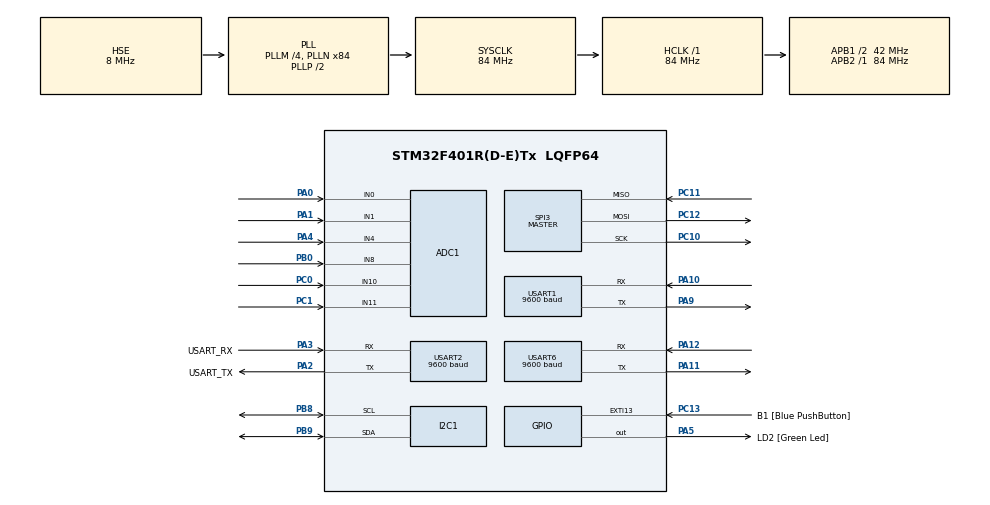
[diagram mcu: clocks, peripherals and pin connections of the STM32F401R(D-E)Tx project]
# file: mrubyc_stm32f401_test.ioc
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ADC1.Channel-0\#ChannelRegularConversion=ADC_CHANNEL_0
ADC1.NbrOfConversionFlag=1
ADC1.Rank-0\#ChannelRegularConversion=1
ADC1.SamplingTime-0\#ChannelRegularConversion=ADC_SAMPLETIME_3CYCLES
ADC1.master=1
Dma.Request0=USART1_RX
Dma.Request1=USART2_RX
Dma.Request2=USART6_RX
Dma.USART1_RX.0.Direction=DMA_PERIPH_TO_MEMORY
Dma.USART1_RX.0.FIFOMode=DMA_FIFOMODE_DISABLE
Dma.USART1_RX.0.Instance=DMA2_Stream2
Dma.USART1_RX.0.MemDataAlignment=DMA_MDATAALIGN_BYTE
Dma.USART1_RX.0.MemInc=DMA_MINC_ENABLE
Dma.USART1_RX.0.Mode=DMA_CIRCULAR
Dma.USART1_RX.0.PeriphDataAlignment=DMA_PDATAALIGN_BYTE
Dma.USART1_RX.0.PeriphInc=DMA_PINC_DISABLE
Dma.USART1_RX.0.Priority=DMA_PRIORITY_LOW
Dma.USART2_RX.1.Direction=DMA_PERIPH_TO_MEMORY
Dma.USART2_RX.1.FIFOMode=DMA_FIFOMODE_DISABLE
Dma.USART2_RX.1.Instance=DMA1_Stream5
Dma.USART2_RX.1.MemDataAlignment=DMA_MDATAALIGN_BYTE
Dma.USART2_RX.1.MemInc=DMA_MINC_ENABLE
Dma.USART2_RX.1.Mode=DMA_CIRCULAR
Dma.USART2_RX.1.PeriphDataAlignment=DMA_PDATAALIGN_BYTE
Dma.USART2_RX.1.PeriphInc=DMA_PINC_DISABLE
Dma.USART2_RX.1.Priority=DMA_PRIORITY_LOW
Dma.USART6_RX.2.Direction=DMA_PERIPH_TO_MEMORY
Dma.USART6_RX.2.FIFOMode=DMA_FIFOMODE_DISABLE
Dma.USART6_RX.2.Instance=DMA2_Stream1
Dma.USART6_RX.2.MemDataAlignment=DMA_MDATAALIGN_BYTE
Dma.USART6_RX.2.MemInc=DMA_MINC_ENABLE
Dma.USART6_RX.2.Mode=DMA_CIRCULAR
Dma.USART6_RX.2.PeriphDataAlignment=DMA_PDATAALIGN_BYTE
Dma.USART6_RX.2.PeriphInc=DMA_PINC_DISABLE
Dma.USART6_RX.2.Priority=DMA_PRIORITY_LOW
Mcu.Family=STM32F4
Mcu.Name=STM32F401R(D-E)Tx
Mcu.Package=LQFP64
NVIC.DMA1_Stream5_IRQn=true\:0\:0\:false\:false\:true\:false\:true\:true
NVIC.DMA2_Stream1_IRQn=true\:0\:0\:false\:false\:true\:false\:true\:true
NVIC.DMA2_Stream2_IRQn=true\:0\:0\:false\:false\:true\:false\:true\:true
NVIC.PriorityGroup=NVIC_PRIORITYGROUP_0
PA0-WKUP.Signal=ADCx_IN0
PA1.Signal=ADCx_IN1
PA10.Mode=Asynchronous
PA10.Signal=USART1_RX
PA11.Mode=Asynchronous
PA11.Signal=USART6_TX
PA12.Mode=Asynchronous
PA12.Signal=USART6_RX
PA13.GPIO_Label=TMS
PA13.Mode=Serial_Wire
PA13.Signal=SYS_JTMS-SWDIO
PA14.GPIO_Label=TCK
PA14.Mode=Serial_Wire
PA14.Signal=SYS_JTCK-SWCLK
PA2.GPIO_Label=USART_TX
PA2.GPIO_Mode=GPIO_MODE_AF_PP
PA2.GPIO_PuPd=GPIO_NOPULL
PA2.GPIO_Speed=GPIO_SPEED_FREQ_LOW
PA2.Mode=Asynchronous
PA2.Signal=USART2_TX
PA3.GPIO_Label=USART_RX
PA3.GPIO_Mode=GPIO_MODE_AF_PP
PA3.GPIO_PuPd=GPIO_NOPULL
PA3.GPIO_Speed=GPIO_SPEED_FREQ_LOW
PA3.Mode=Asynchronous
PA3.Signal=USART2_RX
PA4.Signal=ADCx_IN4
PA5.GPIO_Label=LD2 [Green Led]
PA5.GPIO_Mode=GPIO_MODE_OUTPUT_PP
PA5.GPIO_PuPd=GPIO_NOPULL
PA5.GPIO_Speed=GPIO_SPEED_FREQ_LOW
PA5.Signal=GPIO_Output
PA9.Mode=Asynchronous
PA9.Signal=USART1_TX
PB0.Signal=ADCx_IN8
PB3.GPIO_Label=SWO
PB3.Signal=SYS_JTDO-SWO
PB8.Mode=I2C
PB8.Signal=I2C1_SCL
PB9.Mode=I2C
PB9.Signal=I2C1_SDA
PC0.Signal=ADCx_IN10
PC1.Signal=ADCx_IN11
PC10.Mode=Full_Duplex_Master
PC10.Signal=SPI3_SCK
PC11.Mode=Full_Duplex_Master
PC11.Signal=SPI3_MISO
PC12.Mode=Full_Duplex_Master
PC12.Signal=SPI3_MOSI
PC13-ANTI_TAMP.GPIO_Label=B1 [Blue PushButton]
PC13-ANTI_TAMP.GPIO_ModeDefaultEXTI=GPIO_MODE_IT_FALLING
PC13-ANTI_TAMP.GPIO_PuPd=GPIO_NOPULL
PC13-ANTI_TAMP.Signal=GPXTI13
PC14-OSC32_IN.Mode=LSE-External-Oscillator
PC14-OSC32_IN.Signal=RCC_OSC32_IN
PC15-OSC32_OUT.Mode=LSE-External-Oscillator
PC15-OSC32_OUT.Signal=RCC_OSC32_OUT
PH0\ -\ OSC_IN.Mode=HSE-External-Clock-Source
PH0\ -\ OSC_IN.Signal=RCC_OSC_IN
PH1\ -\ OSC_OUT.Mode=HSE-External-Clock-Source
PH1\ -\ OSC_OUT.Signal=RCC_OSC_OUT
ProjectManager.HeapSize=0x200
ProjectManager.StackSize=0x400
ProjectManager.TargetToolchain=STM32CubeIDE
RCC.48MHZClocksFreq_Value=24000000
RCC.AHBFreq_Value=84000000
RCC.APB1CLKDivider=RCC_HCLK_DIV2
RCC.APB1Freq_Value=42000000
RCC.APB1TimFreq_Value=84000000
RCC.APB2Freq_Value=84000000
RCC.APB2TimFreq_Value=84000000
RCC.CortexFreq_Value=84000000
RCC.HCLKFreq_Value=84000000
RCC.HSE_VALUE=8000000
RCC.HSI_VALUE=16000000
RCC.PLLM=4
RCC.PLLN=84
RCC.PLLQ=7
RCC.PLLSourceVirtual=RCC_PLLSOURCE_HSE
RCC.SYSCLKFreq_VALUE=84000000
RCC.SYSCLKSource=RCC_SYSCLKSOURCE_PLLCLK
RCC.VCOOutputFreq_Value=168000000
SH.ADCx_IN0.0=ADC1_IN0,IN0
SH.ADCx_IN1.0=ADC1_IN1,IN1
SH.ADCx_IN10.0=ADC1_IN10,IN10
SH.ADCx_IN11.0=ADC1_IN11,IN11
SH.ADCx_IN4.0=ADC1_IN4,IN4
SH.ADCx_IN8.0=ADC1_IN8,IN8
SPI3.BaudRatePrescaler=SPI_BAUDRATEPRESCALER_64
SPI3.Direction=SPI_DIRECTION_2LINES
SPI3.Mode=SPI_MODE_MASTER
SPI3.VirtualType=VM_MASTER
TIM1.Channel-PWM\ Generation1\ No\ Output=TIM_CHANNEL_1
TIM1.Period=1
TIM2.Channel-PWM\ Generation1\ No\ Output=TIM_CHANNEL_1
TIM2.Channel-PWM\ Generation2\ No\ Output=TIM_CHANNEL_2
TIM2.Channel-PWM\ Generation3\ No\ Output=TIM_CHANNEL_3
TIM2.Period=1
TIM3.Channel-PWM\ Generation1\ No\ Output=TIM_CHANNEL_1
TIM3.Channel-PWM\ Generation2\ No\ Output=TIM_CHANNEL_2
TIM3.Channel-PWM\ Generation3\ No\ Output=TIM_CHANNEL_3
TIM3.Period=1
TIM4.Channel-PWM\ Generation2\ No\ Output=TIM_CHANNEL_2
TIM4.Period=1
USART1.BaudRate=9600
USART1.VirtualMode=VM_ASYNC
USART2.BaudRate=9600
USART2.VirtualMode=VM_ASYNC
USART6.BaudRate=9600
USART6.VirtualMode=VM_ASYNC
VP_TIM1_VS_ClockSourceINT.Mode=Internal
VP_TIM1_VS_no_output1.Mode=PWM Generation1 No Output
VP_TIM2_VS_ClockSourceINT.Mode=Internal
VP_TIM2_VS_no_output1.Mode=PWM Generation1 No Output
VP_TIM2_VS_no_output2.Mode=PWM Generation2 No Output
VP_TIM2_VS_no_output3.Mode=PWM Generation3 No Output
VP_TIM3_VS_ClockSourceINT.Mode=Internal
VP_TIM3_VS_no_output1.Mode=PWM Generation1 No Output
VP_TIM3_VS_no_output2.Mode=PWM Generation2 No Output
VP_TIM3_VS_no_output3.Mode=PWM Generation3 No Output
VP_TIM4_VS_ClockSourceINT.Mode=Internal
VP_TIM4_VS_no_output2.Mode=PWM Generation2 No Output
board=NUCLEO-F401RE

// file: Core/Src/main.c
/* USER CODE BEGIN Header */
/**
  ******************************************************************************
  * @file           : main.c
  * @brief          : Main program body
  ******************************************************************************
  * @attention
  *
  * Copyright (c) 2024 STMicroelectronics.
  * All rights reserved.
  *
  * This software is licensed under terms that can be found in the LICENSE file
  * in the root directory of this software component.
  * If no LICENSE file comes with this software, it is provided AS-IS.
  *
  ******************************************************************************
  */
/* USER CODE END Header */
#include "main.h"

/* USER CODE BEGIN Includes */
#include <stdio.h>

/* USER CODE END Includes */

ADC_HandleTypeDef hadc1;

I2C_HandleTypeDef hi2c1;

SPI_HandleTypeDef hspi3;

TIM_HandleTypeDef htim1;
TIM_HandleTypeDef htim2;
TIM_HandleTypeDef htim3;
TIM_HandleTypeDef htim4;

UART_HandleTypeDef huart1;
UART_HandleTypeDef huart2;
UART_HandleTypeDef huart6;
DMA_HandleTypeDef hdma_usart1_rx;
DMA_HandleTypeDef hdma_usart2_rx;
DMA_HandleTypeDef hdma_usart6_rx;

void SystemClock_Config(void);
static void MX_GPIO_Init(void);
static void MX_DMA_Init(void);
static void MX_USART2_UART_Init(void);
static void MX_ADC1_Init(void);
static void MX_I2C1_Init(void);
static void MX_SPI3_Init(void);
static void MX_USART1_UART_Init(void);
static void MX_USART6_UART_Init(void);
static void MX_TIM1_Init(void);
static void MX_TIM2_Init(void);
static void MX_TIM3_Init(void);
static void MX_TIM4_Init(void);

int main(void)
{

  /* MCU Configuration--------------------------------------------------------*/

  /* Reset of all peripherals, Initializes the Flash interface and the Systick. */
  HAL_Init();

  /* Configure the system clock */
  SystemClock_Config();

  /* Initialize all configured peripherals */
  MX_GPIO_Init();
  MX_DMA_Init();
  MX_USART2_UART_Init();
  MX_ADC1_Init();
  MX_I2C1_Init();
  MX_SPI3_Init();
  MX_USART1_UART_Init();
  MX_USART6_UART_Init();
  MX_TIM1_Init();
  MX_TIM2_Init();
  MX_TIM3_Init();
  MX_TIM4_Init();
  /* USER CODE BEGIN 2 */
  void start_mrubyc(void);
  start_mrubyc();
  /* USER CODE END 2 */

  /* Infinite loop */
  while (1)
  {

  }
}

void SystemClock_Config(void)
{
  RCC_OscInitTypeDef RCC_OscInitStruct = {0};
  RCC_ClkInitTypeDef RCC_ClkInitStruct = {0};

  /** Configure the main internal regulator output voltage
  */
  __HAL_RCC_PWR_CLK_ENABLE();
  __HAL_PWR_VOLTAGESCALING_CONFIG(PWR_REGULATOR_VOLTAGE_SCALE2);

  /** Initializes the RCC Oscillators according to the specified parameters
  * in the RCC_OscInitTypeDef structure.
  */
  RCC_OscInitStruct.OscillatorType = RCC_OSCILLATORTYPE_HSE;
  RCC_OscInitStruct.HSEState = RCC_HSE_BYPASS;
  RCC_OscInitStruct.PLL.PLLState = RCC_PLL_ON;
  RCC_OscInitStruct.PLL.PLLSource = RCC_PLLSOURCE_HSE;
  RCC_OscInitStruct.PLL.PLLM = 4;
  RCC_OscInitStruct.PLL.PLLN = 84;
  RCC_OscInitStruct.PLL.PLLP = RCC_PLLP_DIV2;
  RCC_OscInitStruct.PLL.PLLQ = 7;
  if (HAL_RCC_OscConfig(&RCC_OscInitStruct) != HAL_OK)
  {
    Error_Handler();
  }

  /** Initializes the CPU, AHB and APB buses clocks
  */
  RCC_ClkInitStruct.ClockType = RCC_CLOCKTYPE_HCLK|RCC_CLOCKTYPE_SYSCLK
                              |RCC_CLOCKTYPE_PCLK1|RCC_CLOCKTYPE_PCLK2;
  RCC_ClkInitStruct.SYSCLKSource = RCC_SYSCLKSOURCE_PLLCLK;
  RCC_ClkInitStruct.AHBCLKDivider = RCC_SYSCLK_DIV1;
  RCC_ClkInitStruct.APB1CLKDivider = RCC_HCLK_DIV2;
  RCC_ClkInitStruct.APB2CLKDivider = RCC_HCLK_DIV1;

  if (HAL_RCC_ClockConfig(&RCC_ClkInitStruct, FLASH_LATENCY_2) != HAL_OK)
  {
    Error_Handler();
  }
}

static void MX_ADC1_Init(void)
{

  ADC_ChannelConfTypeDef sConfig = {0};

  /** Configure the global features of the ADC (Clock, Resolution, Data Alignment and number of conversion)
  */
  hadc1.Instance = ADC1;
  hadc1.Init.ClockPrescaler = ADC_CLOCK_SYNC_PCLK_DIV4;
  hadc1.Init.Resolution = ADC_RESOLUTION_12B;
  hadc1.Init.ScanConvMode = DISABLE;
  hadc1.Init.ContinuousConvMode = DISABLE;
  hadc1.Init.DiscontinuousConvMode = DISABLE;
  hadc1.Init.ExternalTrigConvEdge = ADC_EXTERNALTRIGCONVEDGE_NONE;
  hadc1.Init.ExternalTrigConv = ADC_SOFTWARE_START;
  hadc1.Init.DataAlign = ADC_DATAALIGN_RIGHT;
  hadc1.Init.NbrOfConversion = 1;
  hadc1.Init.DMAContinuousRequests = DISABLE;
  hadc1.Init.EOCSelection = ADC_EOC_SINGLE_CONV;
  if (HAL_ADC_Init(&hadc1) != HAL_OK)
  {
    Error_Handler();
  }

  /** Configure for the selected ADC regular channel its corresponding rank in the sequencer and its sample time.
  */
  sConfig.Channel = ADC_CHANNEL_0;
  sConfig.Rank = 1;
  sConfig.SamplingTime = ADC_SAMPLETIME_3CYCLES;
  if (HAL_ADC_ConfigChannel(&hadc1, &sConfig) != HAL_OK)
  {
    Error_Handler();
  }

}

static void MX_I2C1_Init(void)
{

  hi2c1.Instance = I2C1;
  hi2c1.Init.ClockSpeed = 100000;
  hi2c1.Init.DutyCycle = I2C_DUTYCYCLE_2;
  hi2c1.Init.OwnAddress1 = 0;
  hi2c1.Init.AddressingMode = I2C_ADDRESSINGMODE_7BIT;
  hi2c1.Init.DualAddressMode = I2C_DUALADDRESS_DISABLE;
  hi2c1.Init.OwnAddress2 = 0;
  hi2c1.Init.GeneralCallMode = I2C_GENERALCALL_DISABLE;
  hi2c1.Init.NoStretchMode = I2C_NOSTRETCH_DISABLE;
  if (HAL_I2C_Init(&hi2c1) != HAL_OK)
  {
    Error_Handler();
  }

}

static void MX_SPI3_Init(void)
{

  /* SPI3 parameter configuration*/
  hspi3.Instance = SPI3;
  hspi3.Init.Mode = SPI_MODE_MASTER;
  hspi3.Init.Direction = SPI_DIRECTION_2LINES;
  hspi3.Init.DataSize = SPI_DATASIZE_8BIT;
  hspi3.Init.CLKPolarity = SPI_POLARITY_LOW;
  hspi3.Init.CLKPhase = SPI_PHASE_1EDGE;
  hspi3.Init.NSS = SPI_NSS_SOFT;
  hspi3.Init.BaudRatePrescaler = SPI_BAUDRATEPRESCALER_64;
  hspi3.Init.FirstBit = SPI_FIRSTBIT_MSB;
  hspi3.Init.TIMode = SPI_TIMODE_DISABLE;
  hspi3.Init.CRCCalculation = SPI_CRCCALCULATION_DISABLE;
  hspi3.Init.CRCPolynomial = 10;
  if (HAL_SPI_Init(&hspi3) != HAL_OK)
  {
    Error_Handler();
  }

}

static void MX_TIM1_Init(void)
{

  TIM_ClockConfigTypeDef sClockSourceConfig = {0};
  TIM_MasterConfigTypeDef sMasterConfig = {0};
  TIM_OC_InitTypeDef sConfigOC = {0};
  TIM_BreakDeadTimeConfigTypeDef sBreakDeadTimeConfig = {0};

  htim1.Instance = TIM1;
  htim1.Init.Prescaler = 0;
  htim1.Init.CounterMode = TIM_COUNTERMODE_UP;
  htim1.Init.Period = 1;
  htim1.Init.ClockDivision = TIM_CLOCKDIVISION_DIV1;
  htim1.Init.RepetitionCounter = 0;
  htim1.Init.AutoReloadPreload = TIM_AUTORELOAD_PRELOAD_DISABLE;
  if (HAL_TIM_Base_Init(&htim1) != HAL_OK)
  {
    Error_Handler();
  }
  sClockSourceConfig.ClockSource = TIM_CLOCKSOURCE_INTERNAL;
  if (HAL_TIM_ConfigClockSource(&htim1, &sClockSourceConfig) != HAL_OK)
  {
    Error_Handler();
  }
  if (HAL_TIM_PWM_Init(&htim1) != HAL_OK)
  {
    Error_Handler();
  }
  sMasterConfig.MasterOutputTrigger = TIM_TRGO_RESET;
  sMasterConfig.MasterSlaveMode = TIM_MASTERSLAVEMODE_DISABLE;
  if (HAL_TIMEx_MasterConfigSynchronization(&htim1, &sMasterConfig) != HAL_OK)
  {
    Error_Handler();
  }
  sConfigOC.OCMode = TIM_OCMODE_PWM1;
  sConfigOC.Pulse = 0;
  sConfigOC.OCPolarity = TIM_OCPOLARITY_HIGH;
  sConfigOC.OCNPolarity = TIM_OCNPOLARITY_HIGH;
  sConfigOC.OCFastMode = TIM_OCFAST_DISABLE;
  sConfigOC.OCIdleState = TIM_OCIDLESTATE_RESET;
  sConfigOC.OCNIdleState = TIM_OCNIDLESTATE_RESET;
  if (HAL_TIM_PWM_ConfigChannel(&htim1, &sConfigOC, TIM_CHANNEL_1) != HAL_OK)
  {
    Error_Handler();
  }
  sBreakDeadTimeConfig.OffStateRunMode = TIM_OSSR_DISABLE;
  sBreakDeadTimeConfig.OffStateIDLEMode = TIM_OSSI_DISABLE;
  sBreakDeadTimeConfig.LockLevel = TIM_LOCKLEVEL_OFF;
  sBreakDeadTimeConfig.DeadTime = 0;
  sBreakDeadTimeConfig.BreakState = TIM_BREAK_DISABLE;
  sBreakDeadTimeConfig.BreakPolarity = TIM_BREAKPOLARITY_HIGH;
  sBreakDeadTimeConfig.AutomaticOutput = TIM_AUTOMATICOUTPUT_DISABLE;
  if (HAL_TIMEx_ConfigBreakDeadTime(&htim1, &sBreakDeadTimeConfig) != HAL_OK)
  {
    Error_Handler();
  }

}

static void MX_TIM2_Init(void)
{

  TIM_ClockConfigTypeDef sClockSourceConfig = {0};
  TIM_MasterConfigTypeDef sMasterConfig = {0};
  TIM_OC_InitTypeDef sConfigOC = {0};

  htim2.Instance = TIM2;
  htim2.Init.Prescaler = 0;
  htim2.Init.CounterMode = TIM_COUNTERMODE_UP;
  htim2.Init.Period = 1;
  htim2.Init.ClockDivision = TIM_CLOCKDIVISION_DIV1;
  htim2.Init.AutoReloadPreload = TIM_AUTORELOAD_PRELOAD_DISABLE;
  if (HAL_TIM_Base_Init(&htim2) != HAL_OK)
  {
    Error_Handler();
  }
  sClockSourceConfig.ClockSource = TIM_CLOCKSOURCE_INTERNAL;
  if (HAL_TIM_ConfigClockSource(&htim2, &sClockSourceConfig) != HAL_OK)
  {
    Error_Handler();
  }
  if (HAL_TIM_PWM_Init(&htim2) != HAL_OK)
  {
    Error_Handler();
  }
  sMasterConfig.MasterOutputTrigger = TIM_TRGO_RESET;
  sMasterConfig.MasterSlaveMode = TIM_MASTERSLAVEMODE_DISABLE;
  if (HAL_TIMEx_MasterConfigSynchronization(&htim2, &sMasterConfig) != HAL_OK)
  {
    Error_Handler();
  }
  sConfigOC.OCMode = TIM_OCMODE_PWM1;
  sConfigOC.Pulse = 0;
  sConfigOC.OCPolarity = TIM_OCPOLARITY_HIGH;
  sConfigOC.OCFastMode = TIM_OCFAST_DISABLE;
  if (HAL_TIM_PWM_ConfigChannel(&htim2, &sConfigOC, TIM_CHANNEL_1) != HAL_OK)
  {
    Error_Handler();
  }
  if (HAL_TIM_PWM_ConfigChannel(&htim2, &sConfigOC, TIM_CHANNEL_2) != HAL_OK)
  {
    Error_Handler();
  }
  if (HAL_TIM_PWM_ConfigChannel(&htim2, &sConfigOC, TIM_CHANNEL_3) != HAL_OK)
  {
    Error_Handler();
  }

}

static void MX_TIM3_Init(void)
{

  TIM_ClockConfigTypeDef sClockSourceConfig = {0};
  TIM_MasterConfigTypeDef sMasterConfig = {0};
  TIM_OC_InitTypeDef sConfigOC = {0};

  htim3.Instance = TIM3;
  htim3.Init.Prescaler = 0;
  htim3.Init.CounterMode = TIM_COUNTERMODE_UP;
  htim3.Init.Period = 1;
  htim3.Init.ClockDivision = TIM_CLOCKDIVISION_DIV1;
  htim3.Init.AutoReloadPreload = TIM_AUTORELOAD_PRELOAD_DISABLE;
  if (HAL_TIM_Base_Init(&htim3) != HAL_OK)
  {
    Error_Handler();
  }
  sClockSourceConfig.ClockSource = TIM_CLOCKSOURCE_INTERNAL;
  if (HAL_TIM_ConfigClockSource(&htim3, &sClockSourceConfig) != HAL_OK)
  {
    Error_Handler();
  }
  if (HAL_TIM_PWM_Init(&htim3) != HAL_OK)
  {
    Error_Handler();
  }
  sMasterConfig.MasterOutputTrigger = TIM_TRGO_RESET;
  sMasterConfig.MasterSlaveMode = TIM_MASTERSLAVEMODE_DISABLE;
  if (HAL_TIMEx_MasterConfigSynchronization(&htim3, &sMasterConfig) != HAL_OK)
  {
    Error_Handler();
  }
  sConfigOC.OCMode = TIM_OCMODE_PWM1;
  sConfigOC.Pulse = 0;
  sConfigOC.OCPolarity = TIM_OCPOLARITY_HIGH;
  sConfigOC.OCFastMode = TIM_OCFAST_DISABLE;
  if (HAL_TIM_PWM_ConfigChannel(&htim3, &sConfigOC, TIM_CHANNEL_1) != HAL_OK)
  {
    Error_Handler();
  }
  if (HAL_TIM_PWM_ConfigChannel(&htim3, &sConfigOC, TIM_CHANNEL_2) != HAL_OK)
  {
    Error_Handler();
  }
  if (HAL_TIM_PWM_ConfigChannel(&htim3, &sConfigOC, TIM_CHANNEL_3) != HAL_OK)
  {
    Error_Handler();
  }

}

static void MX_TIM4_Init(void)
{

  TIM_ClockConfigTypeDef sClockSourceConfig = {0};
  TIM_MasterConfigTypeDef sMasterConfig = {0};
  TIM_OC_InitTypeDef sConfigOC = {0};

  htim4.Instance = TIM4;
  htim4.Init.Prescaler = 0;
  htim4.Init.CounterMode = TIM_COUNTERMODE_UP;
  htim4.Init.Period = 1;
  htim4.Init.ClockDivision = TIM_CLOCKDIVISION_DIV1;
  htim4.Init.AutoReloadPreload = TIM_AUTORELOAD_PRELOAD_DISABLE;
  if (HAL_TIM_Base_Init(&htim4) != HAL_OK)
  {
    Error_Handler();
  }
  sClockSourceConfig.ClockSource = TIM_CLOCKSOURCE_INTERNAL;
  if (HAL_TIM_ConfigClockSource(&htim4, &sClockSourceConfig) != HAL_OK)
  {
    Error_Handler();
  }
  if (HAL_TIM_PWM_Init(&htim4) != HAL_OK)
  {
    Error_Handler();
  }
  sMasterConfig.MasterOutputTrigger = TIM_TRGO_RESET;
  sMasterConfig.MasterSlaveMode = TIM_MASTERSLAVEMODE_DISABLE;
  if (HAL_TIMEx_MasterConfigSynchronization(&htim4, &sMasterConfig) != HAL_OK)
  {
    Error_Handler();
  }
  sConfigOC.OCMode = TIM_OCMODE_PWM1;
  sConfigOC.Pulse = 0;
  sConfigOC.OCPolarity = TIM_OCPOLARITY_HIGH;
  sConfigOC.OCFastMode = TIM_OCFAST_DISABLE;
  if (HAL_TIM_PWM_ConfigChannel(&htim4, &sConfigOC, TIM_CHANNEL_2) != HAL_OK)
  {
    Error_Handler();
  }

}

static void MX_USART1_UART_Init(void)
{

  huart1.Instance = USART1;
  huart1.Init.BaudRate = 9600;
  huart1.Init.WordLength = UART_WORDLENGTH_8B;
  huart1.Init.StopBits = UART_STOPBITS_1;
  huart1.Init.Parity = UART_PARITY_NONE;
  huart1.Init.Mode = UART_MODE_TX_RX;
  huart1.Init.HwFlowCtl = UART_HWCONTROL_NONE;
  huart1.Init.OverSampling = UART_OVERSAMPLING_16;
  if (HAL_UART_Init(&huart1) != HAL_OK)
  {
    Error_Handler();
  }

}

static void MX_USART2_UART_Init(void)
{

  huart2.Instance = USART2;
  huart2.Init.BaudRate = 9600;
  huart2.Init.WordLength = UART_WORDLENGTH_8B;
  huart2.Init.StopBits = UART_STOPBITS_1;
  huart2.Init.Parity = UART_PARITY_NONE;
  huart2.Init.Mode = UART_MODE_TX_RX;
  huart2.Init.HwFlowCtl = UART_HWCONTROL_NONE;
  huart2.Init.OverSampling = UART_OVERSAMPLING_16;
  if (HAL_UART_Init(&huart2) != HAL_OK)
  {
    Error_Handler();
  }

}

static void MX_USART6_UART_Init(void)
{

  huart6.Instance = USART6;
  huart6.Init.BaudRate = 9600;
  huart6.Init.WordLength = UART_WORDLENGTH_8B;
  huart6.Init.StopBits = UART_STOPBITS_1;
  huart6.Init.Parity = UART_PARITY_NONE;
  huart6.Init.Mode = UART_MODE_TX_RX;
  huart6.Init.HwFlowCtl = UART_HWCONTROL_NONE;
  huart6.Init.OverSampling = UART_OVERSAMPLING_16;
  if (HAL_UART_Init(&huart6) != HAL_OK)
  {
    Error_Handler();
  }

}

static void MX_DMA_Init(void)
{

  /* DMA controller clock enable */
  __HAL_RCC_DMA2_CLK_ENABLE();
  __HAL_RCC_DMA1_CLK_ENABLE();

  /* DMA interrupt init */
  /* DMA1_Stream5_IRQn interrupt configuration */
  HAL_NVIC_SetPriority(DMA1_Stream5_IRQn, 0, 0);
  HAL_NVIC_EnableIRQ(DMA1_Stream5_IRQn);
  /* DMA2_Stream1_IRQn interrupt configuration */
  HAL_NVIC_SetPriority(DMA2_Stream1_IRQn, 0, 0);
  HAL_NVIC_EnableIRQ(DMA2_Stream1_IRQn);
  /* DMA2_Stream2_IRQn interrupt configuration */
  HAL_NVIC_SetPriority(DMA2_Stream2_IRQn, 0, 0);
  HAL_NVIC_EnableIRQ(DMA2_Stream2_IRQn);

}

static void MX_GPIO_Init(void)
{
  GPIO_InitTypeDef GPIO_InitStruct = {0};

  /* GPIO Ports Clock Enable */
  __HAL_RCC_GPIOC_CLK_ENABLE();
  __HAL_RCC_GPIOH_CLK_ENABLE();
  __HAL_RCC_GPIOA_CLK_ENABLE();
  __HAL_RCC_GPIOB_CLK_ENABLE();
  __HAL_RCC_GPIOD_CLK_ENABLE();

  /*Configure GPIO pin Output Level */
  HAL_GPIO_WritePin(LD2_GPIO_Port, LD2_Pin, GPIO_PIN_RESET);

  /*Configure GPIO pin : B1_Pin */
  GPIO_InitStruct.Pin = B1_Pin;
  GPIO_InitStruct.Mode = GPIO_MODE_IT_FALLING;
  GPIO_InitStruct.Pull = GPIO_NOPULL;
  HAL_GPIO_Init(B1_GPIO_Port, &GPIO_InitStruct);

  /*Configure GPIO pins : PC2 PC3 PC4 PC5
                           PC6 PC7 PC8 PC9 */
  GPIO_InitStruct.Pin = GPIO_PIN_2|GPIO_PIN_3|GPIO_PIN_4|GPIO_PIN_5
                          |GPIO_PIN_6|GPIO_PIN_7|GPIO_PIN_8|GPIO_PIN_9;
  GPIO_InitStruct.Mode = GPIO_MODE_ANALOG;
  GPIO_InitStruct.Pull = GPIO_NOPULL;
  HAL_GPIO_Init(GPIOC, &GPIO_InitStruct);

  /*Configure GPIO pin : LD2_Pin */
  GPIO_InitStruct.Pin = LD2_Pin;
  GPIO_InitStruct.Mode = GPIO_MODE_OUTPUT_PP;
  GPIO_InitStruct.Pull = GPIO_NOPULL;
  GPIO_InitStruct.Speed = GPIO_SPEED_FREQ_LOW;
  HAL_GPIO_Init(LD2_GPIO_Port, &GPIO_InitStruct);

  /*Configure GPIO pins : PA6 PA7 PA8 PA15 */
  GPIO_InitStruct.Pin = GPIO_PIN_6|GPIO_PIN_7|GPIO_PIN_8|GPIO_PIN_15;
  GPIO_InitStruct.Mode = GPIO_MODE_ANALOG;
  GPIO_InitStruct.Pull = GPIO_NOPULL;
  HAL_GPIO_Init(GPIOA, &GPIO_InitStruct);

  /*Configure GPIO pins : PB1 PB2 PB10 PB12
                           PB13 PB14 PB15 PB4
                           PB5 PB6 PB7 */
  GPIO_InitStruct.Pin = GPIO_PIN_1|GPIO_PIN_2|GPIO_PIN_10|GPIO_PIN_12
                          |GPIO_PIN_13|GPIO_PIN_14|GPIO_PIN_15|GPIO_PIN_4
                          |GPIO_PIN_5|GPIO_PIN_6|GPIO_PIN_7;
  GPIO_InitStruct.Mode = GPIO_MODE_ANALOG;
  GPIO_InitStruct.Pull = GPIO_NOPULL;
  HAL_GPIO_Init(GPIOB, &GPIO_InitStruct);

  /*Configure GPIO pin : PD2 */
  GPIO_InitStruct.Pin = GPIO_PIN_2;
  GPIO_InitStruct.Mode = GPIO_MODE_ANALOG;
  GPIO_InitStruct.Pull = GPIO_NOPULL;
  HAL_GPIO_Init(GPIOD, &GPIO_InitStruct);

}

void Error_Handler(void)
{
  __disable_irq();
  while (1)
  {
  }
}

#ifdef  USE_FULL_ASSERT
/**
  * @brief  Reports the name of the source file and the source line number
  *         where the assert_param error has occurred.
  * @param  file: pointer to the source file name
  * @param  line: assert_param error line source number
  * @retval None
  */
void assert_failed(uint8_t *file, uint32_t line)
{
  /* USER CODE BEGIN 6 */
  /* User can add his own implementation to report the file name and line number,
     ex: printf("Wrong parameters value: file %s on line %d\r\n", file, line) */
  printf("Wrong parameters value: file %s on line %ld\r\n", file, line);
  /* USER CODE END 6 */
}
#endif /* USE_FULL_ASSERT */
